AUTOSAR XML (schema 00044)
package /E40_Platform_System_SystemPackage/Components
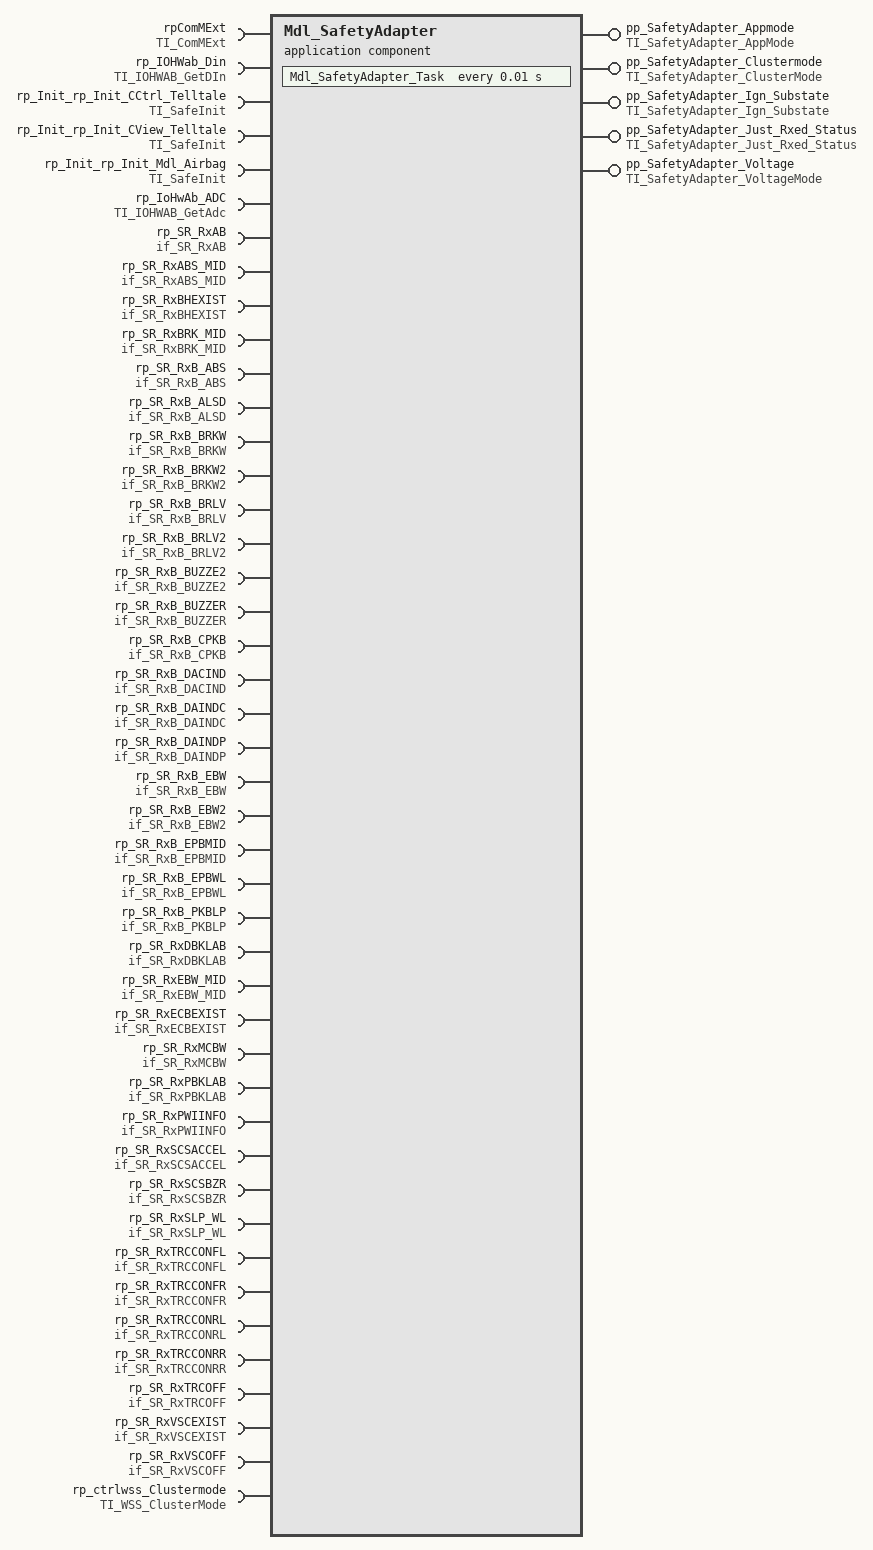
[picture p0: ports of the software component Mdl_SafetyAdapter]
  application sw component type Mdl_SafetyAdapter
    5 x provide port:
      pp_SafetyAdapter_Appmode: nonqueued-sender-com-spec{data-element=SafetyAdapter_AppMode, init-value=constant-reference=Mdl_SafetyAdapterSafetyAdapter_AppModeValue0}, provided-interface=TI_SafetyAdapter_AppMode
      pp_SafetyAdapter_Clustermode: nonqueued-sender-com-spec{data-element=SafetyAdapter_CurrentClusterMode, init-value=constant-reference=Mdl_SafetyAdapterSafetyAdapter_CurrentClusterModeValue0}, provided-interface=TI_SafetyAdapter_ClusterMode
      pp_SafetyAdapter_Ign_Substate: nonqueued-sender-com-spec{data-element=SafetyAdapter_Ign_Substate, init-value=constant-reference=Mdl_SafetyAdapterSafetyAdapter_Ign_SubstateValue0}, provided-interface=TI_SafetyAdapter_Ign_Substate
      pp_SafetyAdapter_Just_Rxed_Status: provided-interface=TI_SafetyAdapter_Just_Rxed_Status
        provided-com-specs:
          operation=RxCan_SignalClearJustRcvdStatus, queue-length=1
          operation=RxCan_SignalGetJustRcvdStatus, queue-length=1
      pp_SafetyAdapter_Voltage: provided-interface=TI_SafetyAdapter_VoltageMode
        provided-com-specs:
          data-element=SafetyAdapter_HVSD1, init-value=constant-reference=Mdl_SafetyAdapterSafetyAdapter_HVSD1Value0
          data-element=SafetyAdapter_LVSD1, init-value=constant-reference=Mdl_SafetyAdapterSafetyAdapter_LVSD1Value0
    44 x require port:
      rpComMExt: required-interface=TI_ComMExt
        required-com-specs:
          CAN_ActivateSilentCommunication
          CAN_CommControlActivateRx
          CAN_CommControlActivateTx
          CAN_CommControlDeActivateRx
          CAN_CommControlDeActivateTx
          CAN_CommControlSetDone
          CAN_DeActivateSilentCommunication
          CAN_GetCurrentComMode
          CAN_ReleaseCommunication
          CAN_RequestCommunication
          GetBusOffStatus
          Get_MCAN_ERR_PIN_Status
          Init
      rp_IOHWab_Din: required-com-specs=[GetAsyncRawInput, GetInputGroup, GetProcessedInput, GetSyncRawInput], required-interface=TI_IOHWAB_GetDIn
      rp_Init_rp_Init_CCtrl_Telltale: client-com-spec=Init, required-interface=TI_SafeInit
      rp_Init_rp_Init_CView_Telltale: client-com-spec=Init, required-interface=TI_SafeInit
      rp_Init_rp_Init_Mdl_Airbag: client-com-spec=Init, required-interface=TI_SafeInit
      rp_IoHwAb_ADC: required-com-specs=[GetAsyncRawAdc, GetProcessedAdc, GetSyncRawAdc], required-interface=TI_IOHWAB_GetAdc
      rp_SR_RxAB: nonqueued-receiver-com-spec{data-element=AB, init-value=constant-reference=Mdl_SafetyAdapterABValue0}, required-interface=if_SR_RxAB
      rp_SR_RxABS_MID: nonqueued-receiver-com-spec{data-element=ABS_MID, init-value=constant-reference=Mdl_SafetyAdapterABS_MIDValue0}, required-interface=if_SR_RxABS_MID
      rp_SR_RxBHEXIST: nonqueued-receiver-com-spec{data-element=BHEXIST, init-value=constant-reference=Mdl_SafetyAdapterBHEXISTValue0}, required-interface=if_SR_RxBHEXIST
      rp_SR_RxBRK_MID: nonqueued-receiver-com-spec{data-element=BRK_MID, init-value=constant-reference=Mdl_SafetyAdapterBRK_MIDValue0}, required-interface=if_SR_RxBRK_MID
      rp_SR_RxB_ABS: nonqueued-receiver-com-spec{data-element=B_ABS, init-value=constant-reference=Mdl_SafetyAdapterB_ABSValue0}, required-interface=if_SR_RxB_ABS
      rp_SR_RxB_ALSD: nonqueued-receiver-com-spec{data-element=B_ALSD, init-value=constant-reference=Mdl_SafetyAdapterB_ALSDValue0}, required-interface=if_SR_RxB_ALSD
      rp_SR_RxB_BRKW: nonqueued-receiver-com-spec{data-element=B_BRKW, init-value=constant-reference=Mdl_SafetyAdapterB_BRKWValue0}, required-interface=if_SR_RxB_BRKW
      rp_SR_RxB_BRKW2: nonqueued-receiver-com-spec{data-element=B_BRKW2, init-value=constant-reference=Mdl_SafetyAdapterB_BRKW2Value0}, required-interface=if_SR_RxB_BRKW2
      rp_SR_RxB_BRLV: nonqueued-receiver-com-spec{data-element=B_BRLV, init-value=constant-reference=Mdl_SafetyAdapterB_BRLVValue0}, required-interface=if_SR_RxB_BRLV
      rp_SR_RxB_BRLV2: nonqueued-receiver-com-spec{data-element=B_BRLV2, init-value=constant-reference=Mdl_SafetyAdapterB_BRLV2Value0}, required-interface=if_SR_RxB_BRLV2
      rp_SR_RxB_BUZZE2: nonqueued-receiver-com-spec{data-element=B_BUZZE2, init-value=constant-reference=Mdl_SafetyAdapterB_BUZZE2Value0}, required-interface=if_SR_RxB_BUZZE2
      rp_SR_RxB_BUZZER: nonqueued-receiver-com-spec{data-element=B_BUZZER, init-value=constant-reference=Mdl_SafetyAdapterB_BUZZERValue0}, required-interface=if_SR_RxB_BUZZER
      rp_SR_RxB_CPKB: nonqueued-receiver-com-spec{data-element=B_CPKB, init-value=constant-reference=Mdl_SafetyAdapterB_CPKBValue0}, required-interface=if_SR_RxB_CPKB
      rp_SR_RxB_DACIND: nonqueued-receiver-com-spec{data-element=B_DACIND, init-value=constant-reference=Mdl_SafetyAdapterB_DACINDValue0}, required-interface=if_SR_RxB_DACIND
      rp_SR_RxB_DAINDC: nonqueued-receiver-com-spec{data-element=B_DAINDC, init-value=constant-reference=Mdl_SafetyAdapterB_DAINDCValue0}, required-interface=if_SR_RxB_DAINDC
      rp_SR_RxB_DAINDP: nonqueued-receiver-com-spec{data-element=B_DAINDP, init-value=constant-reference=Mdl_SafetyAdapterB_DAINDPValue0}, required-interface=if_SR_RxB_DAINDP
      rp_SR_RxB_EBW: nonqueued-receiver-com-spec{data-element=B_EBW, init-value=constant-reference=Mdl_SafetyAdapterB_EBWValue0}, required-interface=if_SR_RxB_EBW
      rp_SR_RxB_EBW2: nonqueued-receiver-com-spec{data-element=B_EBW2, init-value=constant-reference=Mdl_SafetyAdapterB_EBW2Value0}, required-interface=if_SR_RxB_EBW2
      rp_SR_RxB_EPBMID: nonqueued-receiver-com-spec{data-element=B_EPBMID, init-value=constant-reference=Mdl_SafetyAdapterB_EPBMIDValue0}, required-interface=if_SR_RxB_EPBMID
      rp_SR_RxB_EPBWL: nonqueued-receiver-com-spec{data-element=B_EPBWL, init-value=constant-reference=Mdl_SafetyAdapterB_EPBWLValue0}, required-interface=if_SR_RxB_EPBWL
      rp_SR_RxB_PKBLP: nonqueued-receiver-com-spec{data-element=B_PKBLP, init-value=constant-reference=Mdl_SafetyAdapterB_PKBLPValue0}, required-interface=if_SR_RxB_PKBLP
      rp_SR_RxDBKLAB: nonqueued-receiver-com-spec{data-element=DBKLAB, init-value=constant-reference=Mdl_SafetyAdapterDBKLABValue0}, required-interface=if_SR_RxDBKLAB
      rp_SR_RxEBW_MID: nonqueued-receiver-com-spec{data-element=EBW_MID, init-value=constant-reference=Mdl_SafetyAdapterEBW_MIDValue0}, required-interface=if_SR_RxEBW_MID
      rp_SR_RxECBEXIST: nonqueued-receiver-com-spec{data-element=ECBEXIST, init-value=constant-reference=Mdl_SafetyAdapterECBEXISTValue0}, required-interface=if_SR_RxECBEXIST
      rp_SR_RxMCBW: nonqueued-receiver-com-spec{data-element=MCBW, init-value=constant-reference=Mdl_SafetyAdapterMCBWValue0}, required-interface=if_SR_RxMCBW
      rp_SR_RxPBKLAB: nonqueued-receiver-com-spec{data-element=PBKLAB, init-value=constant-reference=Mdl_SafetyAdapterPBKLABValue0}, required-interface=if_SR_RxPBKLAB
      rp_SR_RxPWIINFO: nonqueued-receiver-com-spec{data-element=PWIINFO, init-value=constant-reference=Mdl_SafetyAdapterPWIINFOValue0}, required-interface=if_SR_RxPWIINFO
      rp_SR_RxSCSACCEL: nonqueued-receiver-com-spec{data-element=SCSACCEL, init-value=constant-reference=Mdl_SafetyAdapterSCSACCELValue0}, required-interface=if_SR_RxSCSACCEL
      rp_SR_RxSCSBZR: nonqueued-receiver-com-spec{data-element=SCSBZR, init-value=constant-reference=Mdl_SafetyAdapterSCSBZRValue0}, required-interface=if_SR_RxSCSBZR
      rp_SR_RxSLP_WL: nonqueued-receiver-com-spec{data-element=SLP_WL, init-value=constant-reference=Mdl_SafetyAdapterSLP_WLValue0}, required-interface=if_SR_RxSLP_WL
      rp_SR_RxTRCCONFL: nonqueued-receiver-com-spec{data-element=TRCCONFL, init-value=constant-reference=Mdl_SafetyAdapterTRCCONFLValue0}, required-interface=if_SR_RxTRCCONFL
      rp_SR_RxTRCCONFR: nonqueued-receiver-com-spec{data-element=TRCCONFR, init-value=constant-reference=Mdl_SafetyAdapterTRCCONFRValue0}, required-interface=if_SR_RxTRCCONFR
      rp_SR_RxTRCCONRL: nonqueued-receiver-com-spec{data-element=TRCCONRL, init-value=constant-reference=Mdl_SafetyAdapterTRCCONRLValue0}, required-interface=if_SR_RxTRCCONRL
      rp_SR_RxTRCCONRR: nonqueued-receiver-com-spec{data-element=TRCCONRR, init-value=constant-reference=Mdl_SafetyAdapterTRCCONRRValue0}, required-interface=if_SR_RxTRCCONRR
      rp_SR_RxTRCOFF: nonqueued-receiver-com-spec{data-element=TRCOFF, init-value=constant-reference=Mdl_SafetyAdapterTRCOFFValue0}, required-interface=if_SR_RxTRCOFF
      rp_SR_RxVSCEXIST: nonqueued-receiver-com-spec{data-element=VSCEXIST, init-value=constant-reference=Mdl_SafetyAdapterVSCEXISTValue0}, required-interface=if_SR_RxVSCEXIST
      rp_SR_RxVSCOFF: nonqueued-receiver-com-spec{data-element=VSCOFF, init-value=constant-reference=Mdl_SafetyAdapterVSCOFFValue0}, required-interface=if_SR_RxVSCOFF
      rp_ctrlwss_Clustermode: nonqueued-receiver-com-spec{data-element=WSSCurrentClusterMode, init-value=constant-reference=Mdl_SafetyAdapterWSSCurrentClusterModeValue0}, required-interface=TI_WSS_ClusterMode
    behavior IB_Mdl_SafetyAdapter
      4 x data received event:
        DREMdl_SafetyAdapter_OnDataRx_B_EBW2TrigByB_EBW2: start-on-event=Mdl_SafetyAdapter_OnDataRx_B_EBW2, data=rp_SR_RxB_EBW2.B_EBW2
        DREMdl_SafetyAdapter_OnDataRx_B_PKBLPTrigByB_PKBLP: start-on-event=Mdl_SafetyAdapter_OnDataRx_B_PKBLP, data=rp_SR_RxB_PKBLP.B_PKBLP
        DREMdl_SafetyAdapter_OnDataRx_SCSBZRTrigBySCSBZR: start-on-event=Mdl_SafetyAdapter_OnDataRx_SCSBZR, data=rp_SR_RxSCSBZR.SCSBZR
        DREMdl_SafetyAdapter_OnDataRx_VSCOFFTrigByVSCOFF: start-on-event=Mdl_SafetyAdapter_OnDataRx_VSCOFF, data=rp_SR_RxVSCOFF.VSCOFF
      operation invoked event OIE_pp_SafetyAdapter_Just_Rxed_Status_Mdl_SafetyAdapter_RxCan_SignalClearJustRcvdStatusTrigByRxCan_SignalClearJustRcvdStatus: start-on-event=Mdl_SafetyAdapter_RxCan_SignalClearJustRcvdStatus, operation=pp_SafetyAdapter_Just_Rxed_Status.RxCan_SignalClearJustRcvdStatus
      operation invoked event OIE_pp_SafetyAdapter_Just_Rxed_Status_Mdl_SafetyAdapter_RxCan_SignalGetJustRcvdStatusTrigByRxCan_SignalGetJustRcvdStatus: start-on-event=Mdl_SafetyAdapter_RxCan_SignalGetJustRcvdStatus, operation=pp_SafetyAdapter_Just_Rxed_Status.RxCan_SignalGetJustRcvdStatus
      timing event TEMdl_SafetyAdapter_Task: start-on-event=Mdl_SafetyAdapter_Task, period=0.01
      port-api-options:
        enable-take-address=false, indirect-api=false, port=pp_SafetyAdapter_Appmode
        enable-take-address=false, indirect-api=false, port=pp_SafetyAdapter_Clustermode
        enable-take-address=false, indirect-api=false, port=pp_SafetyAdapter_Ign_Substate
        enable-take-address=false, indirect-api=false, port=pp_SafetyAdapter_Just_Rxed_Status
        enable-take-address=false, indirect-api=false, port=pp_SafetyAdapter_Voltage
        enable-take-address=false, indirect-api=false, port=rpComMExt
        enable-take-address=false, indirect-api=false, port=rp_IOHWab_Din
        enable-take-address=false, indirect-api=false, port=rp_Init_rp_Init_CCtrl_Telltale
        enable-take-address=false, indirect-api=false, port=rp_Init_rp_Init_CView_Telltale
        enable-take-address=false, indirect-api=false, port=rp_Init_rp_Init_Mdl_Airbag
        enable-take-address=false, indirect-api=false, port=rp_IoHwAb_ADC
        enable-take-address=false, indirect-api=false, port=rp_SR_RxAB
        enable-take-address=false, indirect-api=false, port=rp_SR_RxABS_MID
        enable-take-address=false, indirect-api=false, port=rp_SR_RxBHEXIST
        enable-take-address=false, indirect-api=false, port=rp_SR_RxBRK_MID
        enable-take-address=false, indirect-api=false, port=rp_SR_RxB_ABS
        enable-take-address=false, indirect-api=false, port=rp_SR_RxB_ALSD
        enable-take-address=false, indirect-api=false, port=rp_SR_RxB_BRKW
        enable-take-address=false, indirect-api=false, port=rp_SR_RxB_BRKW2
        enable-take-address=false, indirect-api=false, port=rp_SR_RxB_BRLV
        enable-take-address=false, indirect-api=false, port=rp_SR_RxB_BRLV2
        enable-take-address=false, indirect-api=false, port=rp_SR_RxB_BUZZE2
        enable-take-address=false, indirect-api=false, port=rp_SR_RxB_BUZZER
        enable-take-address=false, indirect-api=false, port=rp_SR_RxB_CPKB
        enable-take-address=false, indirect-api=false, port=rp_SR_RxB_DACIND
        enable-take-address=false, indirect-api=false, port=rp_SR_RxB_DAINDC
        enable-take-address=false, indirect-api=false, port=rp_SR_RxB_DAINDP
        enable-take-address=false, indirect-api=false, port=rp_SR_RxB_EBW
        enable-take-address=false, indirect-api=false, port=rp_SR_RxB_EBW2
        enable-take-address=false, indirect-api=false, port=rp_SR_RxB_EPBMID
        enable-take-address=false, indirect-api=false, port=rp_SR_RxB_EPBWL
        enable-take-address=false, indirect-api=false, port=rp_SR_RxB_PKBLP
        enable-take-address=false, indirect-api=false, port=rp_SR_RxDBKLAB
        enable-take-address=false, indirect-api=false, port=rp_SR_RxEBW_MID
        enable-take-address=false, indirect-api=false, port=rp_SR_RxECBEXIST
        enable-take-address=false, indirect-api=false, port=rp_SR_RxMCBW
        enable-take-address=false, indirect-api=false, port=rp_SR_RxPBKLAB
        enable-take-address=false, indirect-api=false, port=rp_SR_RxPWIINFO
        enable-take-address=false, indirect-api=false, port=rp_SR_RxSCSACCEL
        enable-take-address=false, indirect-api=false, port=rp_SR_RxSCSBZR
        enable-take-address=false, indirect-api=false, port=rp_SR_RxSLP_WL
        enable-take-address=false, indirect-api=false, port=rp_SR_RxTRCCONFL
        enable-take-address=false, indirect-api=false, port=rp_SR_RxTRCCONFR
        enable-take-address=false, indirect-api=false, port=rp_SR_RxTRCCONRL
        enable-take-address=false, indirect-api=false, port=rp_SR_RxTRCCONRR
        enable-take-address=false, indirect-api=false, port=rp_SR_RxTRCOFF
        enable-take-address=false, indirect-api=false, port=rp_SR_RxVSCEXIST
        enable-take-address=false, indirect-api=false, port=rp_SR_RxVSCOFF
        enable-take-address=false, indirect-api=false, port=rp_ctrlwss_Clustermode
      7 x runnable, all with can-be-invoked-concurrently=true:
        Mdl_SafetyAdapter_OnDataRx_B_EBW2
        Mdl_SafetyAdapter_OnDataRx_B_PKBLP
        Mdl_SafetyAdapter_OnDataRx_SCSBZR
        Mdl_SafetyAdapter_OnDataRx_VSCOFF
        Mdl_SafetyAdapter_RxCan_SignalClearJustRcvdStatus
        Mdl_SafetyAdapter_RxCan_SignalGetJustRcvdStatus
        Mdl_SafetyAdapter_Task
          data-receive-point-by-arguments:
            38 x access:
              DRA_rp_SR_RxAB_AB: accessed-variable=rp_SR_RxAB.AB
              DRA_rp_SR_RxABS_MID_ABS_MID: accessed-variable=rp_SR_RxABS_MID.ABS_MID
              DRA_rp_SR_RxBHEXIST_BHEXIST: accessed-variable=rp_SR_RxBHEXIST.BHEXIST
              DRA_rp_SR_RxBRK_MID_BRK_MID: accessed-variable=rp_SR_RxBRK_MID.BRK_MID
              DRA_rp_SR_RxB_ABS_B_ABS: accessed-variable=rp_SR_RxB_ABS.B_ABS
              DRA_rp_SR_RxB_ALSD_B_ALSD: accessed-variable=rp_SR_RxB_ALSD.B_ALSD
              DRA_rp_SR_RxB_BRKW_B_BRKW: accessed-variable=rp_SR_RxB_BRKW.B_BRKW
              DRA_rp_SR_RxB_BRKW2_B_BRKW2: accessed-variable=rp_SR_RxB_BRKW2.B_BRKW2
              DRA_rp_SR_RxB_BRLV_B_BRLV: accessed-variable=rp_SR_RxB_BRLV.B_BRLV
              DRA_rp_SR_RxB_BRLV2_B_BRLV2: accessed-variable=rp_SR_RxB_BRLV2.B_BRLV2
              DRA_rp_SR_RxB_BUZZE2_B_BUZZE2: accessed-variable=rp_SR_RxB_BUZZE2.B_BUZZE2
              DRA_rp_SR_RxB_BUZZER_B_BUZZER: accessed-variable=rp_SR_RxB_BUZZER.B_BUZZER
              DRA_rp_SR_RxB_CPKB_B_CPKB: accessed-variable=rp_SR_RxB_CPKB.B_CPKB
              DRA_rp_SR_RxB_DACIND_B_DACIND: accessed-variable=rp_SR_RxB_DACIND.B_DACIND
              DRA_rp_SR_RxB_DAINDC_B_DAINDC: accessed-variable=rp_SR_RxB_DAINDC.B_DAINDC
              DRA_rp_SR_RxB_DAINDP_B_DAINDP: accessed-variable=rp_SR_RxB_DAINDP.B_DAINDP
              DRA_rp_SR_RxB_EBW_B_EBW: accessed-variable=rp_SR_RxB_EBW.B_EBW
              DRA_rp_SR_RxB_EBW2_B_EBW2: accessed-variable=rp_SR_RxB_EBW2.B_EBW2
              DRA_rp_SR_RxB_EPBMID_B_EPBMID: accessed-variable=rp_SR_RxB_EPBMID.B_EPBMID
              DRA_rp_SR_RxB_EPBWL_B_EPBWL: accessed-variable=rp_SR_RxB_EPBWL.B_EPBWL
              DRA_rp_SR_RxB_PKBLP_B_PKBLP: accessed-variable=rp_SR_RxB_PKBLP.B_PKBLP
              DRA_rp_SR_RxDBKLAB_DBKLAB: accessed-variable=rp_SR_RxDBKLAB.DBKLAB
              DRA_rp_SR_RxEBW_MID_EBW_MID: accessed-variable=rp_SR_RxEBW_MID.EBW_MID
              DRA_rp_SR_RxECBEXIST_ECBEXIST: accessed-variable=rp_SR_RxECBEXIST.ECBEXIST
              DRA_rp_SR_RxMCBW_MCBW: accessed-variable=rp_SR_RxMCBW.MCBW
              DRA_rp_SR_RxPBKLAB_PBKLAB: accessed-variable=rp_SR_RxPBKLAB.PBKLAB
              DRA_rp_SR_RxPWIINFO_PWIINFO: accessed-variable=rp_SR_RxPWIINFO.PWIINFO
              DRA_rp_SR_RxSCSACCEL_SCSACCEL: accessed-variable=rp_SR_RxSCSACCEL.SCSACCEL
              DRA_rp_SR_RxSCSBZR_SCSBZR: accessed-variable=rp_SR_RxSCSBZR.SCSBZR
              DRA_rp_SR_RxSLP_WL_SLP_WL: accessed-variable=rp_SR_RxSLP_WL.SLP_WL
              DRA_rp_SR_RxTRCCONFL_TRCCONFL: accessed-variable=rp_SR_RxTRCCONFL.TRCCONFL
              DRA_rp_SR_RxTRCCONFR_TRCCONFR: accessed-variable=rp_SR_RxTRCCONFR.TRCCONFR
              DRA_rp_SR_RxTRCCONRL_TRCCONRL: accessed-variable=rp_SR_RxTRCCONRL.TRCCONRL
              DRA_rp_SR_RxTRCCONRR_TRCCONRR: accessed-variable=rp_SR_RxTRCCONRR.TRCCONRR
              DRA_rp_SR_RxTRCOFF_TRCOFF: accessed-variable=rp_SR_RxTRCOFF.TRCOFF
              DRA_rp_SR_RxVSCEXIST_VSCEXIST: accessed-variable=rp_SR_RxVSCEXIST.VSCEXIST
              DRA_rp_SR_RxVSCOFF_VSCOFF: accessed-variable=rp_SR_RxVSCOFF.VSCOFF
              DRA_rp_ctrlwss_Clustermode_WSSCurrentClusterMode: accessed-variable=rp_ctrlwss_Clustermode.WSSCurrentClusterMode
          data-send-points:
            5 x access:
              DWA_pp_SafetyAdapter_Appmode_SafetyAdapter_AppMode: accessed-variable=pp_SafetyAdapter_Appmode.SafetyAdapter_AppMode
              DWA_pp_SafetyAdapter_Clustermode_SafetyAdapter_CurrentClusterMode: accessed-variable=pp_SafetyAdapter_Clustermode.SafetyAdapter_CurrentClusterMode
              DWA_pp_SafetyAdapter_Ign_Substate_SafetyAdapter_Ign_Substate: accessed-variable=pp_SafetyAdapter_Ign_Substate.SafetyAdapter_Ign_Substate
              DWA_pp_SafetyAdapter_Voltage_SafetyAdapter_HVSD1: accessed-variable=pp_SafetyAdapter_Voltage.SafetyAdapter_HVSD1
              DWA_pp_SafetyAdapter_Voltage_SafetyAdapter_LVSD1: accessed-variable=pp_SafetyAdapter_Voltage.SafetyAdapter_LVSD1
          23 x sync call:
            OA_rpComMExt_Get_MCAN_ERR_PIN_Status: operation=rpComMExt.Get_MCAN_ERR_PIN_Status
            OA_rpComMExt_Init: operation=rpComMExt.Init
            OA_rpComMExt_GetBusOffStatus: operation=rpComMExt.GetBusOffStatus
            OA_rpComMExt_CAN_RequestCommunication: operation=rpComMExt.CAN_RequestCommunication
            OA_rpComMExt_CAN_GetCurrentComMode: operation=rpComMExt.CAN_GetCurrentComMode
            OA_rpComMExt_CAN_ReleaseCommunication: operation=rpComMExt.CAN_ReleaseCommunication
            OA_rpComMExt_CAN_DeActivateSilentCommunication: operation=rpComMExt.CAN_DeActivateSilentCommunication
            OA_rpComMExt_CAN_CommControlSetDone: operation=rpComMExt.CAN_CommControlSetDone
            OA_rpComMExt_CAN_CommControlDeActivateTx: operation=rpComMExt.CAN_CommControlDeActivateTx
            OA_rpComMExt_CAN_CommControlDeActivateRx: operation=rpComMExt.CAN_CommControlDeActivateRx
            OA_rpComMExt_CAN_ActivateSilentCommunication: operation=rpComMExt.CAN_ActivateSilentCommunication
            OA_rpComMExt_CAN_CommControlActivateRx: operation=rpComMExt.CAN_CommControlActivateRx
            OA_rpComMExt_CAN_CommControlActivateTx: operation=rpComMExt.CAN_CommControlActivateTx
            OA_rp_IOHWab_Din_GetAsyncRawInput: operation=rp_IOHWab_Din.GetAsyncRawInput
            OA_rp_IOHWab_Din_GetProcessedInput: operation=rp_IOHWab_Din.GetProcessedInput
            OA_rp_IOHWab_Din_GetSyncRawInput: operation=rp_IOHWab_Din.GetSyncRawInput
            OA_rp_IOHWab_Din_GetInputGroup: operation=rp_IOHWab_Din.GetInputGroup
            OA_rp_Init_rp_Init_CCtrl_Telltale_Init: operation=rp_Init_rp_Init_CCtrl_Telltale.Init
            OA_rp_Init_rp_Init_CView_Telltale_Init: operation=rp_Init_rp_Init_CView_Telltale.Init
            OA_rp_Init_rp_Init_Mdl_Airbag_Init: operation=rp_Init_rp_Init_Mdl_Airbag.Init
            OA_rp_IoHwAb_ADC_GetAsyncRawAdc: operation=rp_IoHwAb_ADC.GetAsyncRawAdc
            OA_rp_IoHwAb_ADC_GetSyncRawAdc: operation=rp_IoHwAb_ADC.GetSyncRawAdc
            OA_rp_IoHwAb_ADC_GetProcessedAdc: operation=rp_IoHwAb_ADC.GetProcessedAdc
  swc implementation IMPL_Mdl_SafetyAdapter: behavior=IB_Mdl_SafetyAdapter
